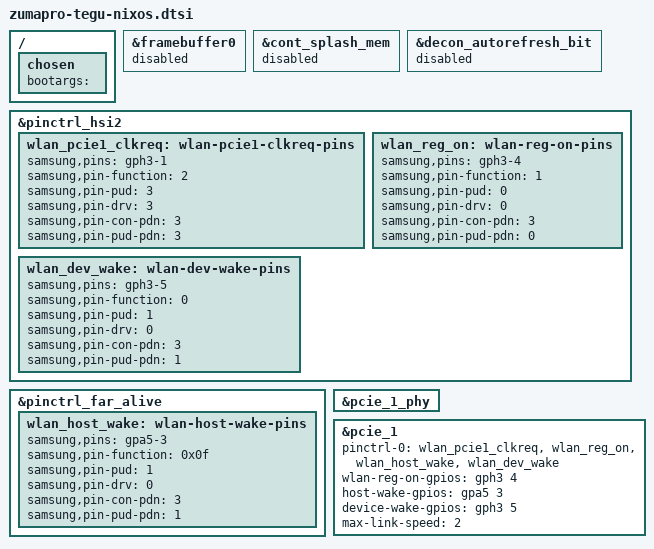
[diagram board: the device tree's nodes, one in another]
// SPDX-License-Identifier: GPL-2.0-only
/*
 * NixOS deltas for the Pixel 9a (tegu), appended to the shared port tree's
 * arch/arm64/boot/dts/exynos/google/zumapro-tegu.dts by ../kernel/apply.sh.
 *
 * Kept as small as it can be: everything else about this board -- the SoC
 * description, pinctrl, the PMIC rails, UFS, the touchscreen on
 * spi@111d0000, both watchdogs, the 8 GiB memory layout -- comes from that
 * tree unchanged, and is better than what this port wrote by hand.
 */

#include <dt-bindings/gpio/gpio.h>

/ {
	chosen {
		/*
		 * ABL concatenates the boot image's cmdline onto whatever is
		 * here, and ../images.nix already passes init=, both consoles,
		 * the fbcon font and the panic policy. The shared tree's
		 * bootargs are postmarketOS's: keeping them would put a
		 * second, different set of console= and *_ignore_unused
		 * arguments in front of ours, and the last console= is the one
		 * that becomes /dev/console. The property still has to exist,
		 * because the bootloader crashes when it is absent.
		 */
		bootargs = "";
	};
};

/*
 * The shared tree puts the bootloader's logo on screen with a
 * simple-framebuffer node plus an mmio-init-helper that pokes DECON's
 * autorefresh bit at 0x19470030. This port uses ../kernel/zumapro-bootfb.c
 * for the same job: it reads geometry, stride and pixel format back out of
 * DECON instead of hard-coding them, reserves the buffer NOMAP before
 * memblock init, and keeps triggering the panel (which is command-mode, so it
 * only shows a frame when told to). Two owners of TRIG_CON, or two simpledrm
 * devices for one buffer, is worse than either alone -- so those two nodes
 * stay off here.
 *
 * cont_splash_mem goes with them. It reserves the same buffer, but bootfb's
 * early_param runs before the device tree's reserved-memory scan and has
 * already marked the range NOMAP by then, so all the node can do is fail:
 *   OF: reserved mem: failed to reserve memory for node 'splash@fac00000'
 */
&framebuffer0 {
	status = "disabled";
};

&cont_splash_mem {
	status = "disabled";
};

&decon_autorefresh_bit {
	status = "disabled";
};

/*
 * Wi-Fi: the board's Broadcom combo chip sits on PCIe channel 1 (HSI2).
 *
 * The shared tree leaves pcie_1 and its phy disabled, and only enables them for
 * the boards it lists as BCM4390 carriers -- caiman, komodo, tokay and comet --
 * with a note that "tegu uses a different part". The vendor's own tegu device
 * tree settles it: the dtb inside the factory's vendor_kernel_boot.img has
 *
 *   pcie@13120000   gpios = <&gph3 0 1>            PERST on gph3-0
 *                   pinctrl-0 = clkreq, perst       gph3-1 (func 2), gph3-0 (func 1)
 *                   ch-num = <1>, num-lanes = <1>   this channel
 *                   no power-domains                so none is added here
 *   its dtbo overlay  max-link-speed = <2>          Gen2, overriding the base's Gen3
 *   its wlan node     wl_reg_on gph3-4, wl_host_wake gpa5-3, wl_dev_wake gph3-5
 *
 * The shared tree's pcie1_clkreq/pcie1_perst groups are gph2-1/gph2-0 -- gs101's
 * routing, and nothing on zumapro uses those pins -- so this defines its own
 * groups with the vendor's pins rather than reusing those labels.
 *
 * The GPIO properties are the names mainline actually reads: brcmfmac finds
 * WL_HOST_WAKE / WL_DEV_WAKE on the PCIe host controller node (it reaches it
 * through the host bridge, because the endpoint has no node of its own), and
 * pci-exynos drives wlan-reg-on-gpios for link enumeration. The vendor's
 * bcmdhd-only properties (pcie,wlan-gpio, the android,bcmdhd_wlan node) are not
 * repeated: the out-of-tree dhd driver is not built here.
 *
 * reset-gpios is deliberately absent from this first cut even though the vendor
 * puts PERST on gph3-0: zumapro.dtsi configures this port's UFS with
 * pinctrl-0 = <&ufs_rst_n &ufs_refclk_out>, and ufs_refclk_out is gph3-0 as
 * well. Claiming that pin as a PCIe reset is the one thing here that could take
 * the root filesystem down, so the link gets its chance with clkreq alone first.
 */
&pinctrl_hsi2 {
	wlan_pcie1_clkreq: wlan-pcie1-clkreq-pins {
		samsung,pins = "gph3-1";
		samsung,pin-function = <2>;
		samsung,pin-pud = <3>;
		samsung,pin-drv = <3>;
		samsung,pin-con-pdn = <3>;
		samsung,pin-pud-pdn = <3>;
	};

	wlan_reg_on: wlan-reg-on-pins {
		samsung,pins = "gph3-4";
		samsung,pin-function = <1>;		/* output */
		samsung,pin-pud = <0>;
		samsung,pin-drv = <0>;
		samsung,pin-con-pdn = <3>;
		samsung,pin-pud-pdn = <0>;
	};

	wlan_dev_wake: wlan-dev-wake-pins {
		samsung,pins = "gph3-5";
		samsung,pin-function = <0>;		/* input */
		samsung,pin-pud = <1>;
		samsung,pin-drv = <0>;
		samsung,pin-con-pdn = <3>;
		samsung,pin-pud-pdn = <1>;
	};
};

&pinctrl_far_alive {
	wlan_host_wake: wlan-host-wake-pins {
		samsung,pins = "gpa5-3";
		samsung,pin-function = <0x0f>;
		samsung,pin-pud = <1>;
		samsung,pin-drv = <0>;
		samsung,pin-con-pdn = <3>;
		samsung,pin-pud-pdn = <1>;
	};
};

&pcie_1_phy {
	status = "okay";
};

&pcie_1 {
	pinctrl-names = "default";
	pinctrl-0 = <&wlan_pcie1_clkreq &wlan_reg_on &wlan_host_wake &wlan_dev_wake>;
	wlan-reg-on-gpios = <&gph3 4 GPIO_ACTIVE_HIGH>;		/* WLAN_EN */
	host-wake-gpios = <&gpa5 3 GPIO_ACTIVE_HIGH>;		/* WL_HOST_WAKE */
	device-wake-gpios = <&gph3 5 GPIO_ACTIVE_HIGH>;		/* WL_DEV_WAKE */
	max-link-speed = <2>;					/* Gen2, per the dtbo overlay */
	status = "okay";
};
